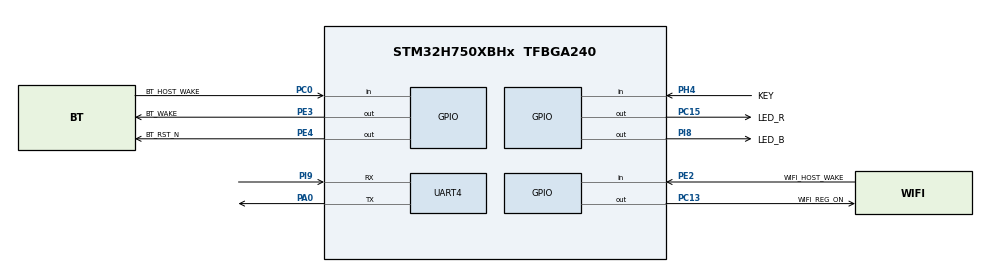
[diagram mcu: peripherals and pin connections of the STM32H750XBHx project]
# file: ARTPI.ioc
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Dma.Request0=UART4_RX
Dma.UART4_RX.0.Direction=DMA_PERIPH_TO_MEMORY
Dma.UART4_RX.0.EventEnable=DISABLE
Dma.UART4_RX.0.FIFOMode=DMA_FIFOMODE_DISABLE
Dma.UART4_RX.0.Instance=DMA1_Stream0
Dma.UART4_RX.0.MemDataAlignment=DMA_MDATAALIGN_BYTE
Dma.UART4_RX.0.MemInc=DMA_MINC_ENABLE
Dma.UART4_RX.0.Mode=DMA_CIRCULAR
Dma.UART4_RX.0.PeriphDataAlignment=DMA_PDATAALIGN_BYTE
Dma.UART4_RX.0.PeriphInc=DMA_PINC_DISABLE
Dma.UART4_RX.0.Polarity=HAL_DMAMUX_REQ_GEN_RISING
Dma.UART4_RX.0.Priority=DMA_PRIORITY_LOW
Dma.UART4_RX.0.RequestNumber=1
Dma.UART4_RX.0.SignalID=NONE
Dma.UART4_RX.0.SyncEnable=DISABLE
Dma.UART4_RX.0.SyncPolarity=HAL_DMAMUX_SYNC_NO_EVENT
Dma.UART4_RX.0.SyncRequestNumber=1
Dma.UART4_RX.0.SyncSignalID=NONE
Mcu.Family=STM32H7
Mcu.Name=STM32H750XBHx
Mcu.Package=TFBGA240
NVIC.DMA1_Stream0_IRQn=true\:0\:0\:false\:false\:true\:true\:false\:true\:true
NVIC.PriorityGroup=NVIC_PRIORITYGROUP_4
NVIC.TIM17_IRQn=true\:15\:0\:false\:false\:true\:false\:false\:true\:true
NVIC.TimeBase=TIM17_IRQn
NVIC.TimeBaseIP=TIM17
NVIC.UART4_IRQn=true\:5\:0\:true\:false\:true\:false\:true\:true\:true
PA0.Mode=Asynchronous
PA0.Signal=UART4_TX
PB10.Signal=USART3_TX
PB11.Signal=USART3_RX
PB14.Signal=SDMMC2_D0
PB15.Signal=SDMMC2_D1
PB3\ (JTDO/TRACESWO).Signal=SDMMC2_D2
PB4\ (NJTRST).Signal=SDMMC2_D3
PC0.GPIO_Label=BT_HOST_WAKE
PC0.Signal=GPIO_Input
PC13.GPIO_Label=WIFI_REG_ON
PC13.PinState=GPIO_PIN_RESET
PC13.Signal=GPIO_Output
PC15-OSC32_OUT\ (OSC32_OUT).GPIO_Label=LED_R
PC15-OSC32_OUT\ (OSC32_OUT).Signal=GPIO_Output
PD11.Signal=USART3_CTS
PD12.Signal=USART3_RTS
PD6.Signal=SDMMC2_CK
PD7.Signal=SDMMC2_CMD
PE2.GPIO_Label=WIFI_HOST_WAKE
PE2.Signal=GPIO_Input
PE3.GPIO_Label=BT_WAKE
PE3.PinState=GPIO_PIN_RESET
PE3.Signal=GPIO_Output
PE4.GPIO_Label=BT_RST_N
PE4.PinState=GPIO_PIN_RESET
PE4.Signal=GPIO_Output
PF10.Signal=QUADSPI_CLK
PF6.Signal=QUADSPI_BK1_IO3
PF7.Signal=QUADSPI_BK1_IO2
PF8.Signal=QUADSPI_BK1_IO0
PF9.Signal=QUADSPI_BK1_IO1
PG6.Signal=QUADSPI_BK1_NCS
PH0-OSC_IN\ (PH0).Mode=HSE-External-Oscillator
PH0-OSC_IN\ (PH0).Signal=RCC_OSC_IN
PH1-OSC_OUT\ (PH1).Mode=HSE-External-Oscillator
PH1-OSC_OUT\ (PH1).Signal=RCC_OSC_OUT
PH11.GPIO_Pu=GPIO_PULLUP
PH11.GPIO_PuPd=GPIO_PULLUP
PH11.GPIO_Speed=GPIO_SPEED_FREQ_HIGH
PH11.Signal=I2C4_SCL
PH12.GPIO_Pu=GPIO_PULLUP
PH12.GPIO_PuPd=GPIO_PULLUP
PH12.GPIO_Speed=GPIO_SPEED_FREQ_HIGH
PH12.Signal=I2C4_SDA
PH4.GPIO_Label=KEY
PH4.Signal=GPIO_Input
PI8.GPIO_Label=LED_B
PI8.PinState=GPIO_PIN_RESET
PI8.Signal=GPIO_Output
PI9.Mode=Asynchronous
PI9.Signal=UART4_RX
ProjectManager.HeapSize=0x200
ProjectManager.StackSize=0x400
ProjectManager.TargetToolchain=MDK-ARM V5
RCC.ADCFreq_Value=50390625
RCC.APB1Freq_Value=120000000
RCC.APB2Freq_Value=120000000
RCC.APB3Freq_Value=120000000
RCC.APB4Freq_Value=120000000
RCC.CortexFreq_Value=480000000
RCC.D1PPRE=RCC_APB3_DIV2
RCC.D2PPRE1=RCC_APB1_DIV2
RCC.D2PPRE2=RCC_APB2_DIV2
RCC.D3PPRE=RCC_APB4_DIV2
RCC.DIVM1=5
RCC.DIVN1=192
RCC.DIVQ1=15
RCC.HCLKFreq_Value=240000000
RCC.HPRE=RCC_HCLK_DIV2
RCC.PLL2FRACN=0
RCC.PLL3FRACN=0
RCC.PLLFRACN=0
RCC.PLLSourceVirtual=RCC_PLLSOURCE_HSE
RCC.PWR_Regulator_Voltage_Scale=PWR_REGULATOR_VOLTAGE_SCALE0
RCC.SYSCLKFreq_VALUE=480000000
RCC.SYSCLKSource=RCC_SYSCLKSOURCE_PLLCLK
RCC.USBFreq_Value=64000000
STMicroelectronics.X-CUBE-AZRTOS-H7.3.3.0.TX_APP_CREATION=1
STMicroelectronics.X-CUBE-AZRTOS-H7.3.3.0.TX_APP_GENERATE_INIT_CODE=false
STMicroelectronics.X-CUBE-AZRTOS-H7.3.3.0.TX_TIMER_TICKS_PER_SECOND=1000
STMicroelectronics.X-CUBE-AZRTOS-H7.3.3.0.ThreadXCcRTOSJjThreadXJjCore=true
STMicroelectronics.X-CUBE-AZRTOS-H7.3.3.0.USBX_DEVICE_SYS_SIZE=4096
STMicroelectronics.X-CUBE-AZRTOS-H7.3.3.0.UX_DEVICE_APP_MEM_POOL_SIZE=10240
STMicroelectronics.X-CUBE-AZRTOS-H7.3.3.0_IsAnAzureRtosMw=true
VP_MEMORYMAP_VS_MEMORYMAP.Mode=CurAppReg
VP_STMicroelectronics.X-CUBE-AZRTOS-H7_VS_RTOSJjThreadX_6.4.0_3.3.0.Mode=RTOSJjThreadX
VP_SYS_VS_tim17.Mode=TIM17
board=custom

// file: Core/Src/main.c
/* USER CODE BEGIN Header */
/**
  ******************************************************************************
  * @file           : main.c
  * @brief          : Main program body
  ******************************************************************************
  * @attention
  *
  * Copyright (c) 2026 STMicroelectronics.
  * All rights reserved.
  *
  * This software is licensed under terms that can be found in the LICENSE file
  * in the root directory of this software component.
  * If no LICENSE file comes with this software, it is provided AS-IS.
  *
  ******************************************************************************
  */
/* USER CODE END Header */
#include "app_threadx.h"
#include "main.h"
#include "dma.h"
#include "memorymap.h"
#include "usart.h"
#include "gpio.h"

/* USER CODE BEGIN Includes */
#include "ldc_easy.h"

/* USER CODE END Includes */

void SystemClock_Config(void);

int main(void)
{

  /* MCU Configuration--------------------------------------------------------*/

  /* Reset of all peripherals, Initializes the Flash interface and the Systick. */
  HAL_Init();

  /* Configure the system clock */
  SystemClock_Config();

  /* Initialize all configured peripherals */
  MX_GPIO_Init();
  MX_DMA_Init();
  MX_UART4_Init();

  MX_ThreadX_Init();

  /* We should never get here as control is now taken by the scheduler */

  /* Infinite loop */
  while (1)
  {

  }
}

void SystemClock_Config(void)
{
  RCC_OscInitTypeDef RCC_OscInitStruct = {0};
  RCC_ClkInitTypeDef RCC_ClkInitStruct = {0};

  /** Supply configuration update enable
  */
  HAL_PWREx_ConfigSupply(PWR_LDO_SUPPLY);

  /** Configure the main internal regulator output voltage
  */
  __HAL_PWR_VOLTAGESCALING_CONFIG(PWR_REGULATOR_VOLTAGE_SCALE0);

  while(!__HAL_PWR_GET_FLAG(PWR_FLAG_VOSRDY)) {}

  /** Initializes the RCC Oscillators according to the specified parameters
  * in the RCC_OscInitTypeDef structure.
  */
  RCC_OscInitStruct.OscillatorType = RCC_OSCILLATORTYPE_HSE;
  RCC_OscInitStruct.HSEState = RCC_HSE_ON;
  RCC_OscInitStruct.PLL.PLLState = RCC_PLL_ON;
  RCC_OscInitStruct.PLL.PLLSource = RCC_PLLSOURCE_HSE;
  RCC_OscInitStruct.PLL.PLLM = 5;
  RCC_OscInitStruct.PLL.PLLN = 192;
  RCC_OscInitStruct.PLL.PLLP = 2;
  RCC_OscInitStruct.PLL.PLLQ = 15;
  RCC_OscInitStruct.PLL.PLLR = 2;
  RCC_OscInitStruct.PLL.PLLRGE = RCC_PLL1VCIRANGE_2;
  RCC_OscInitStruct.PLL.PLLVCOSEL = RCC_PLL1VCOWIDE;
  RCC_OscInitStruct.PLL.PLLFRACN = 0;
  if (HAL_RCC_OscConfig(&RCC_OscInitStruct) != HAL_OK)
  {
    Error_Handler();
  }

  /** Initializes the CPU, AHB and APB buses clocks
  */
  RCC_ClkInitStruct.ClockType = RCC_CLOCKTYPE_HCLK|RCC_CLOCKTYPE_SYSCLK
                              |RCC_CLOCKTYPE_PCLK1|RCC_CLOCKTYPE_PCLK2
                              |RCC_CLOCKTYPE_D3PCLK1|RCC_CLOCKTYPE_D1PCLK1;
  RCC_ClkInitStruct.SYSCLKSource = RCC_SYSCLKSOURCE_PLLCLK;
  RCC_ClkInitStruct.SYSCLKDivider = RCC_SYSCLK_DIV1;
  RCC_ClkInitStruct.AHBCLKDivider = RCC_HCLK_DIV2;
  RCC_ClkInitStruct.APB3CLKDivider = RCC_APB3_DIV2;
  RCC_ClkInitStruct.APB1CLKDivider = RCC_APB1_DIV2;
  RCC_ClkInitStruct.APB2CLKDivider = RCC_APB2_DIV2;
  RCC_ClkInitStruct.APB4CLKDivider = RCC_APB4_DIV2;

  if (HAL_RCC_ClockConfig(&RCC_ClkInitStruct, FLASH_LATENCY_4) != HAL_OK)
  {
    Error_Handler();
  }
}

void HAL_TIM_PeriodElapsedCallback(TIM_HandleTypeDef *htim)
{
  if (htim->Instance == TIM17)
  {
    HAL_IncTick();
    ldc_easy_tick_all(1U);
  }
}

void Error_Handler(void)
{
  __disable_irq();
  while (1)
  {
  }
}
